VERSION ""

NS_ :

BS_:

BU_:

BO_ 768 HS_CAN5__300: 2 Vector__XXX
 SG_ Veh_Speed_CAN5__ : 15|8@0+ (1,0) [0|255] "" Vector__XXX
 SG_ ACC_Radar_active_CAN5__ : 4|1@0+ (1,0) [0|1] "" Vector__XXX

BO_ 1024 HS_CAN5__400: 1 Vector__XXX
 SG_ ACC_Radar_active2_CAN5__ : 4|1@0+ (1,0) [0|1] "" Vector__XXX

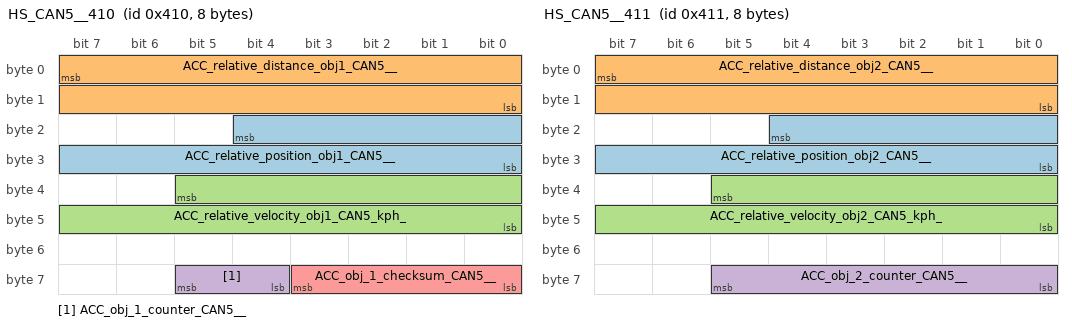
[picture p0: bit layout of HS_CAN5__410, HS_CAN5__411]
BO_ 1040 HS_CAN5__410: 8 Vector__XXX
 SG_ ACC_relative_position_obj1_CAN5__ : 20|13@0- (1,0) [-4095|4095] "" Vector__XXX
 SG_ ACC_relative_distance_obj1_CAN5__ : 7|16@0+ (0.00775,0) [0|4095.9375] "m" Vector__XXX
 SG_ ACC_relative_velocity_obj1_CAN5_kph_ : 37|14@0- (0.056,0) [-8191|8191] "kph" Vector__XXX
 SG_ ACC_obj_1_counter_CAN5__ : 61|2@0+ (1,0) [0|3] "" Vector__XXX
 SG_ ACC_obj_1_checksum_CAN5__ : 59|4@0+ (1,0) [0|15] "" Vector__XXX

BO_ 1041 HS_CAN5__411: 8 Vector__XXX
 SG_ ACC_relative_position_obj2_CAN5__ : 20|13@0- (1,0) [-4095|4095] "" Vector__XXX
 SG_ ACC_relative_distance_obj2_CAN5__ : 7|16@0+ (0.00775,0) [0|65535] "m" Vector__XXX
 SG_ ACC_relative_velocity_obj2_CAN5_kph_ : 37|14@0- (0.056,0) [-8191|8191] "kph" Vector__XXX
 SG_ ACC_obj_2_counter_CAN5__ : 61|6@0+ (1,0) [0|63] "" Vector__XXX

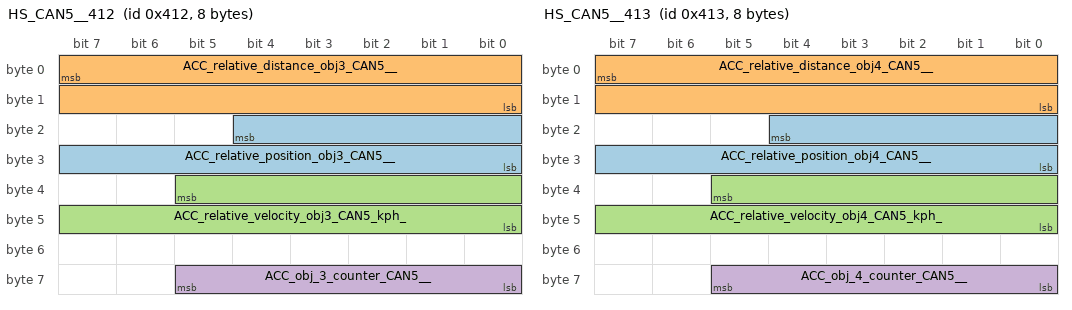
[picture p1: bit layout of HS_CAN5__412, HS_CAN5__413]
BO_ 1042 HS_CAN5__412: 8 Vector__XXX
 SG_ ACC_relative_position_obj3_CAN5__ : 20|13@0- (1,0) [-4095|4095] "" Vector__XXX
 SG_ ACC_relative_distance_obj3_CAN5__ : 7|16@0+ (0.00775,0) [0|65535] "m" Vector__XXX
 SG_ ACC_relative_velocity_obj3_CAN5_kph_ : 37|14@0- (0.056,0) [-8191|8191] "kph" Vector__XXX
 SG_ ACC_obj_3_counter_CAN5__ : 61|6@0+ (1,0) [0|63] "" Vector__XXX

BO_ 1043 HS_CAN5__413: 8 Vector__XXX
 SG_ ACC_relative_position_obj4_CAN5__ : 20|13@0- (1,0) [-4095|4095] "" Vector__XXX
 SG_ ACC_relative_distance_obj4_CAN5__ : 7|16@0+ (0.00775,0) [0|65535] "m" Vector__XXX
 SG_ ACC_relative_velocity_obj4_CAN5_kph_ : 37|14@0- (0.056,0) [-8191|8191] "kph" Vector__XXX
 SG_ ACC_obj_4_counter_CAN5__ : 61|6@0+ (1,0) [0|63] "" Vector__XXX

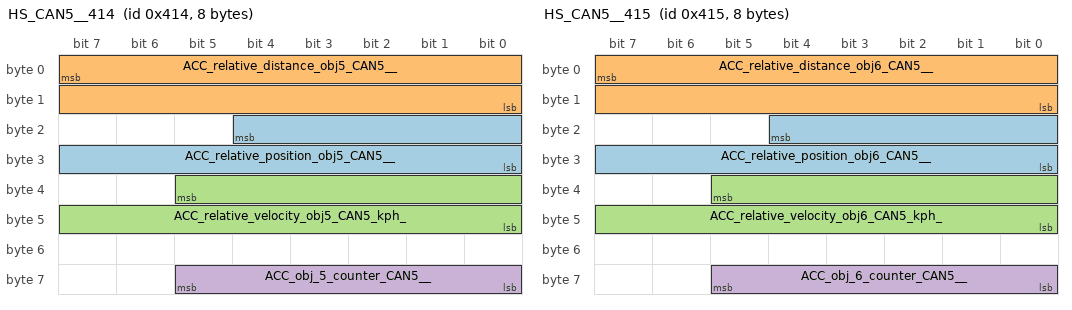
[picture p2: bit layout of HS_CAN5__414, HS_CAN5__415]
BO_ 1044 HS_CAN5__414: 8 Vector__XXX
 SG_ ACC_relative_position_obj5_CAN5__ : 20|13@0- (1,0) [-4095|4095] "" Vector__XXX
 SG_ ACC_relative_distance_obj5_CAN5__ : 7|16@0+ (0.00775,0) [0|65535] "m" Vector__XXX
 SG_ ACC_relative_velocity_obj5_CAN5_kph_ : 37|14@0- (0.056,0) [-8191|8191] "kph" Vector__XXX
 SG_ ACC_obj_5_counter_CAN5__ : 61|6@0+ (1,0) [0|63] "" Vector__XXX

BO_ 1045 HS_CAN5__415: 8 Vector__XXX
 SG_ ACC_relative_position_obj6_CAN5__ : 20|13@0- (1,0) [-4095|4095] "" Vector__XXX
 SG_ ACC_relative_distance_obj6_CAN5__ : 7|16@0+ (0.00775,0) [0|65535] "m" Vector__XXX
 SG_ ACC_relative_velocity_obj6_CAN5_kph_ : 37|14@0- (0.056,0) [-8191|8191] "kph" Vector__XXX
 SG_ ACC_obj_6_counter_CAN5__ : 61|6@0+ (1,0) [0|63] "" Vector__XXX

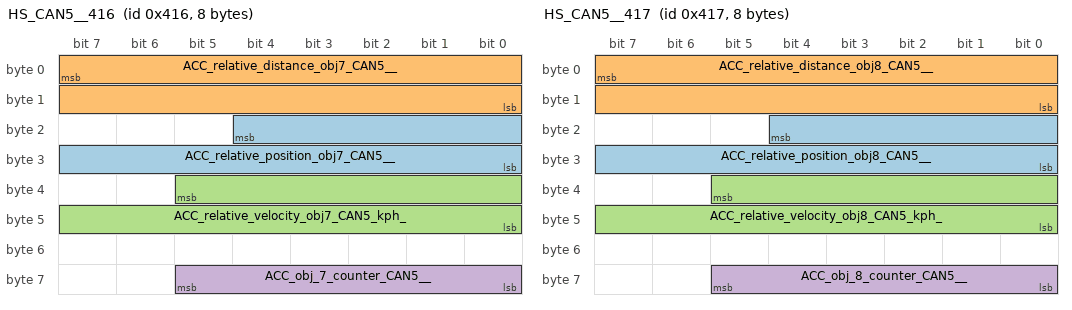
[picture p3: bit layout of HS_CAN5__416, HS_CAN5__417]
BO_ 1046 HS_CAN5__416: 8 Vector__XXX
 SG_ ACC_relative_position_obj7_CAN5__ : 20|13@0- (1,0) [-4095|4095] "" Vector__XXX
 SG_ ACC_relative_distance_obj7_CAN5__ : 7|16@0+ (0.00775,0) [0|65535] "m" Vector__XXX
 SG_ ACC_relative_velocity_obj7_CAN5_kph_ : 37|14@0- (0.056,0) [-8191|8191] "kph" Vector__XXX
 SG_ ACC_obj_7_counter_CAN5__ : 61|6@0+ (1,0) [0|63] "" Vector__XXX

BO_ 1047 HS_CAN5__417: 8 Vector__XXX
 SG_ ACC_relative_position_obj8_CAN5__ : 20|13@0- (1,0) [-4095|4095] "" Vector__XXX
 SG_ ACC_relative_distance_obj8_CAN5__ : 7|16@0+ (0.00775,0) [0|65535] "m" Vector__XXX
 SG_ ACC_relative_velocity_obj8_CAN5_kph_ : 37|14@0- (0.056,0) [-8191|8191] "kph" Vector__XXX
 SG_ ACC_obj_8_counter_CAN5__ : 61|6@0+ (1,0) [0|63] "" Vector__XXX

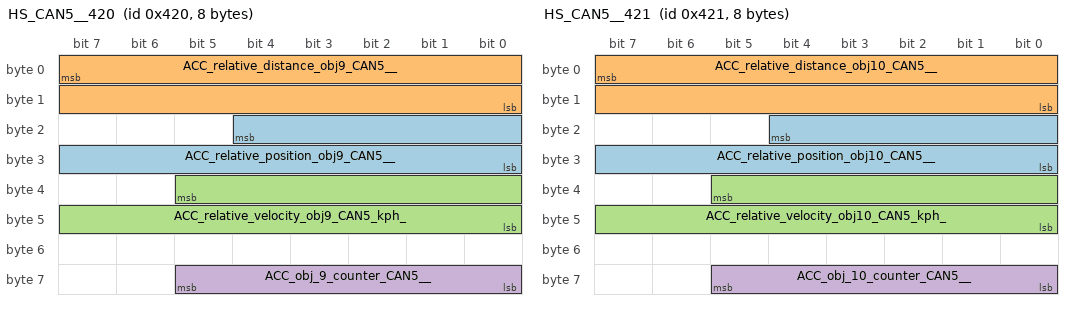
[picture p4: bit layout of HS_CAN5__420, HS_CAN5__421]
BO_ 1056 HS_CAN5__420: 8 Vector__XXX
 SG_ ACC_relative_position_obj9_CAN5__ : 20|13@0- (1,0) [-4095|4095] "" Vector__XXX
 SG_ ACC_relative_distance_obj9_CAN5__ : 7|16@0+ (0.00775,0) [0|65535] "m" Vector__XXX
 SG_ ACC_relative_velocity_obj9_CAN5_kph_ : 37|14@0- (0.056,0) [-8191|8191] "kph" Vector__XXX
 SG_ ACC_obj_9_counter_CAN5__ : 61|6@0+ (1,0) [0|63] "" Vector__XXX

BO_ 1057 HS_CAN5__421: 8 Vector__XXX
 SG_ ACC_relative_position_obj10_CAN5__ : 20|13@0- (1,0) [-4095|4095] "" Vector__XXX
 SG_ ACC_relative_distance_obj10_CAN5__ : 7|16@0+ (0.00775,0) [0|65535] "m" Vector__XXX
 SG_ ACC_relative_velocity_obj10_CAN5_kph_ : 37|14@0- (0.056,0) [-8191|8191] "kph" Vector__XXX
 SG_ ACC_obj_10_counter_CAN5__ : 61|6@0+ (1,0) [0|63] "" Vector__XXX

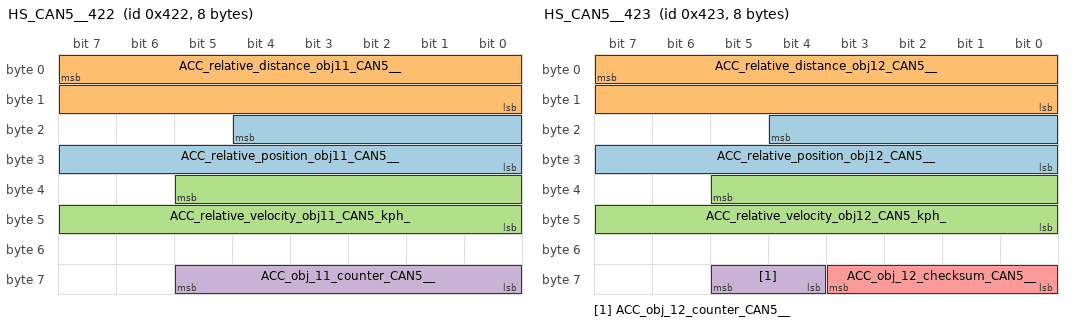
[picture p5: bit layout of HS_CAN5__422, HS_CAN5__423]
BO_ 1058 HS_CAN5__422: 8 Vector__XXX
 SG_ ACC_relative_position_obj11_CAN5__ : 20|13@0- (1,0) [-4095|4095] "" Vector__XXX
 SG_ ACC_relative_distance_obj11_CAN5__ : 7|16@0+ (0.00775,0) [0|65535] "m" Vector__XXX
 SG_ ACC_relative_velocity_obj11_CAN5_kph_ : 37|14@0- (0.056,0) [-8191|8191] "kph" Vector__XXX
 SG_ ACC_obj_11_counter_CAN5__ : 61|6@0+ (1,0) [0|63] "" Vector__XXX

BO_ 1059 HS_CAN5__423: 8 Vector__XXX
 SG_ ACC_relative_position_obj12_CAN5__ : 20|13@0- (1,0) [-4095|4095] "" Vector__XXX
 SG_ ACC_relative_distance_obj12_CAN5__ : 7|16@0+ (0.00775,0) [0|65535] "m" Vector__XXX
 SG_ ACC_relative_velocity_obj12_CAN5_kph_ : 37|14@0- (0.056,0) [-8191|8191] "kph" Vector__XXX
 SG_ ACC_obj_12_counter_CAN5__ : 61|2@0+ (1,0) [0|3] "" Vector__XXX
 SG_ ACC_obj_12_checksum_CAN5__ : 59|4@0+ (1,0) [0|15] "" Vector__XXX

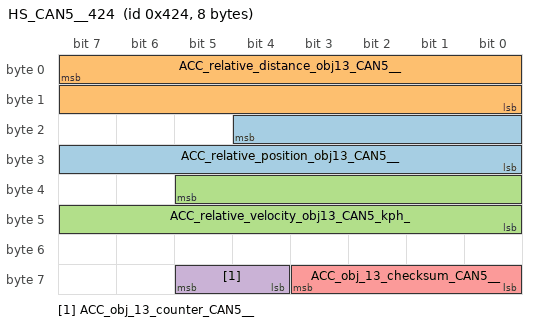
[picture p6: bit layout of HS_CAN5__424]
BO_ 1060 HS_CAN5__424: 8 Vector__XXX
 SG_ ACC_relative_position_obj13_CAN5__ : 20|13@0- (1,0) [-4095|4095] "" Vector__XXX
 SG_ ACC_relative_distance_obj13_CAN5__ : 7|16@0+ (0.00775,0) [0|65535] "m" Vector__XXX
 SG_ ACC_relative_velocity_obj13_CAN5_kph_ : 37|14@0- (0.056,0) [-8191|8191] "kph" Vector__XXX
 SG_ ACC_obj_13_counter_CAN5__ : 61|2@0+ (1,0) [0|3] "" Vector__XXX
 SG_ ACC_obj_13_checksum_CAN5__ : 59|4@0+ (1,0) [0|15] "" Vector__XXX
